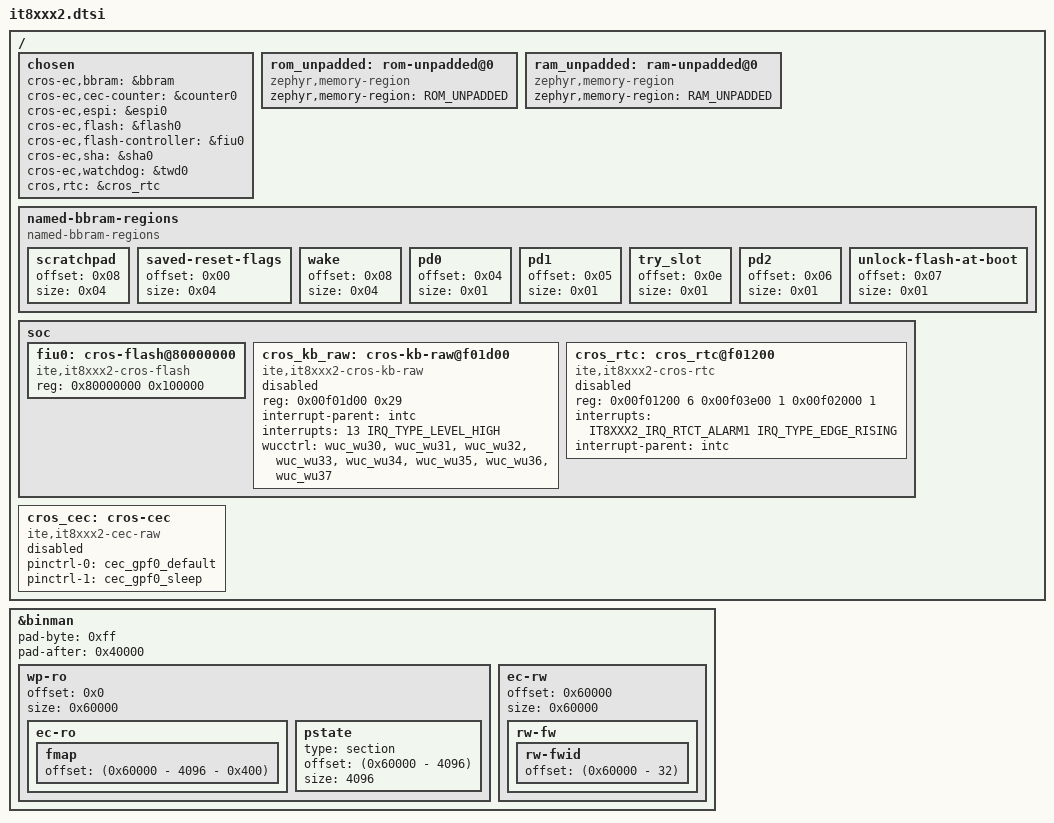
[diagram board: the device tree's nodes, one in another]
/* Copyright 2021 The ChromiumOS Authors
 * Use of this source code is governed by a BSD-style license that can be
 * found in the LICENSE file.
 */

#include <cros/binman.dtsi>

/ {
	chosen {
		cros-ec,bbram = &bbram;
		cros-ec,cec-counter = &counter0;
		cros-ec,espi = &espi0;
		cros-ec,flash = &flash0;
		cros-ec,flash-controller = &fiu0;
		cros-ec,sha = &sha0;
		cros-ec,watchdog = &twd0;
		cros,rtc = &cros_rtc;
	};

	/*
	 * The 'reg' property for these unpadded tracking regions is intentionally omitted.
	 * Board definitions must include the appropriate ROM and RAM override files
	 * (e.g., #include "it8xxx2_1m_rom.dtsi" and #include "it8xxx2_60k_ram.dtsi")
	 * to explicitly declare the physical sizes of the chip variant.
	 */
	rom_unpadded: rom-unpadded@0 {
		compatible = "zephyr,memory-region";
		zephyr,memory-region = "ROM_UNPADDED";
	};
	ram_unpadded: ram-unpadded@0 {
		compatible = "zephyr,memory-region";
		zephyr,memory-region = "RAM_UNPADDED";
	};
	named-bbram-regions {
		compatible = "named-bbram-regions";

		scratchpad {
			offset = <0x08>;
			size = <0x04>;
		};
		saved-reset-flags {
			offset = <0x00>;
			size = <0x04>;
		};
		wake {
			offset = <0x08>;
			size = <0x04>;
		};
		pd0 {
			offset = <0x04>;
			size = <0x01>;
		};
		pd1 {
			offset = <0x05>;
			size = <0x01>;
		};
		try_slot {
			offset = <0x0e>;
			size = <0x01>;
		};
		pd2 {
			offset = <0x06>;
			size = <0x01>;
		};
		unlock-flash-at-boot {
			offset = <0x07>;
			size = <0x01>;
		};
	};

	soc {
		fiu0: cros-flash@80000000 {
			compatible = "ite,it8xxx2-cros-flash";
			reg = <0x80000000 0x100000>;
		};

		cros_kb_raw: cros-kb-raw@f01d00 {
			compatible = "ite,it8xxx2-cros-kb-raw";
			reg = <0x00f01d00 0x29>;
			interrupt-parent = <&intc>;
			interrupts = <13 IRQ_TYPE_LEVEL_HIGH>;
			wucctrl = <&wuc_wu30   /* KSI[0] */
				   &wuc_wu31   /* KSI[1] */
				   &wuc_wu32   /* KSI[2] */
				   &wuc_wu33   /* KSI[3] */
				   &wuc_wu34   /* KSI[4] */
				   &wuc_wu35   /* KSI[5] */
				   &wuc_wu36   /* KSI[6] */
				   &wuc_wu37>; /* KSI[7] */
			status = "disabled";
		};

		cros_rtc: cros_rtc@f01200 {
			compatible = "ite,it8xxx2-cros-rtc";
			reg = <0x00f01200 6   /* EC2I */
			       0x00f03e00 1   /* GPIOGCR */
			       0x00f02000 1>; /* GCTRL */
			interrupts = <IT8XXX2_IRQ_RTCT_ALARM1 IRQ_TYPE_EDGE_RISING>;
			interrupt-parent = <&intc>;
			status = "disabled";
		};
	};

	cros_cec: cros-cec {
		compatible = "ite,it8xxx2-cec-raw";
		pinctrl-0 = <&cec_gpf0_default>;
		pinctrl-1 = <&cec_gpf0_sleep>;
		pinctrl-names = "default", "sleep";
		status = "disabled";
	};

	/* it8xxx2 has 1MB of flash. currently, we use 768KB from flash. */
};

&binman {
	pad-byte = <0xff>;
	pad-after = <0x40000>;

	wp-ro {
		offset = <0x0>;
		size = <0x60000>;

		ec-ro {
			fmap {
				offset = <(0x60000 - 4096 - 0x400)>;
				/*
				 * don't specify 'size = <0x400>' here so
				 * it is auto-assigned to the fmap size.
				 */
			};
		};
		pstate: pstate {
			type = "section";
			offset = <(0x60000 - 4096)>;
			size = <4096>;
		};
	};
	ec-rw {
		offset = <0x60000>;
		size = <0x60000>;
		rw-fw {
			rw-fwid {
				/* Fix the lcoation of the FWID to the
				 * last 32 bytes of the flash. This
				 * ensures the RW entries in the FMAP
				 * stored in the RO section of flash
				 * are always correct.
				 */
				offset = <(0x60000 - 32)>;
			};
		};
	};
};
